# MB9BF51xN register map
File version: 1.8
CPU: 
Registers are 8-bit, read-write, reset 0x0 unless marked. A register's access mark holds for its fields unless they carry their own. Offsets are from the block's base; [hi:lo] are bit positions; {n}, {i} and the like mark numbered series.

## INTREQ — Interrupts
Base 0x40031000
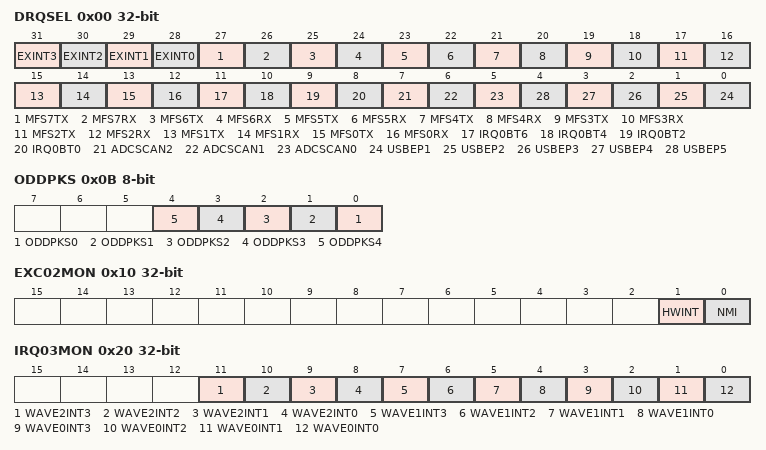
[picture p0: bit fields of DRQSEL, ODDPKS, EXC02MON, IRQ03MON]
0x00 DRQSEL 32-bit — DMA Request Selection Register
  [31] EXINT3 — The interrupt signal of the external interrupt ch.3 is output as a transfer request to the DMAC (including extension).
  [30] EXINT2 — The interrupt signal of the external interrupt ch.2 is output as a transfer request to the DMAC (including extension).
  [29] EXINT1 — The interrupt signal of the external interrupt ch.1 is output as a transfer request to the DMAC (including extension).
  [28] EXINT0 — The interrupt signal of the external interrupt ch.0 is output as a transfer request to the DMAC (including extension).
  [27] MFS7TX — The transmission interrupt signal of the MFS ch.7 is output as a transfer request to the DMAC (including extension).
  [26] MFS7RX — The reception interrupt signal of the MFS ch.7 is output as a transfer request to the DMAC (including extension).
  [25] MFS6TX — The transmission interrupt signal of the MFS ch.6 is output as a transfer request to the DMAC (including extension).
  [24] MFS6RX — The reception interrupt signal of the MFS ch.6 is output as a transfer request to the DMAC (including extension).
  [23] MFS5TX — The transmission interrupt signal of the MFS ch.5 is output as a transfer request to the DMAC (including extension).
  [22] MFS5RX — The reception interrupt signal of the MFS ch.5 is output as a transfer request to the DMAC (including extension).
  [21] MFS4TX — The transmission interrupt signal of the MFS ch.4 is output as a transfer request to the DMAC (including extension).
  [20] MFS4RX — The reception interrupt signal of the MFS ch.4 is output as a transfer request to the DMAC (including extension).
  [19] MFS3TX — The transmission interrupt signal of the MFS ch.3 is output as a transfer request to the DMAC (including extension).
  [18] MFS3RX — The reception interrupt signal of the MFS ch.3 is output as a transfer request to the DMAC (including extension).
  [17] MFS2TX — The transmission interrupt signal of the MFS ch.2 is output as a transfer request to the DMAC (including extension).
  [16] MFS2RX — The reception interrupt signal of the MFS ch.2 is output as a transfer request to the DMAC (including extension).
  [15] MFS1TX — The transmission interrupt signal of the MFS ch.1 is output as a transfer request to the DMAC (including extension).
  [14] MFS1RX — The reception interrupt signal of the MFS ch.1 is output as a transfer request to the DMAC (including extension).
  [13] MFS0TX — The transmission interrupt signal of the MFS ch.0 is output as a transfer request to the DMAC (including extension).
  [12] MFS0RX — The reception interrupt signal of the MFS ch.0 is output as a transfer request to the DMAC (including extension).
  [11] IRQ0BT6 — The IRQ0 interrupt signal of the base timer ch.6 is output as a transfer request to the DMAC.
  [10] IRQ0BT4 — The IRQ0 interrupt signal of the base timer ch.4 is output as a transfer request to the DMAC.
  [9] IRQ0BT2 — The IRQ0 interrupt signal of the base timer ch.3 is output as a transfer request to the DMAC.
  [8] IRQ0BT0 — The IRQ0 interrupt signal of the base timer ch.0 is output as a transfer request to the DMAC.
  [7] ADCSCAN2 — The scan conversion interrupt signal of the A/D converter unit 2 is output as a transfer request to the DMAC.
  [6] ADCSCAN1 — The scan conversion interrupt signal of the A/D converter unit 1 is output as a transfer request to the DMAC.
  [5] ADCSCAN0 — The scan conversion interrupt signal of the A/D converter unit 0 is output as a transfer request to the DMAC.
  [n-1] USBEP{n} (n=1..5) — The EP{n} DRQ interrupt signal of the USB ch.0 is output as a transfer request to the DMAC.
0x0B ODDPKS — USB ch.0 Odd Packet Size DMA Enable Register
  [n] ODDPKS{n} (n=0..4) — "When the transfer destination address of DMAC is USB.EP{n+1}DT, the bit width of the last transfer data is converted to Byte."
0x0C IRQCMODE 32-bit — Interrupt Factor Vector Relocate Setting Register
  [0] IRQCMODE — Interrupt Factor Vector Relocate Setting
0x10 EXC02MON 32-bit ro — EXC02 batch read register
  [1] HWINT — Hardware watchdog timer interrupt request
  [0] NMI — External NMIX pin interrupt request
0x14 IRQ00MON 32-bit ro — IRQ00 Batch Read Register
  [0] FCSINT — Anomalous frequency detection by CSV interrupt request
0x18 IRQ01MON 32-bit ro — IRQ01 Batch Read Register
  [0] SWWDTINT — Software watchdog timer interrupt request
0x1C IRQ02MON 32-bit ro — IRQ02 Batch Read Register
  [0] LVDINT — Low voltage detection (LVD) interrupt request
0x20 IRQ03MON 32-bit ro — IRQ03 Batch Read Register
  [11] WAVE2INT3 — WFG timer 54 interrupt request in MFT unit 2
  [10] WAVE2INT2 — WFG timer 32 interrupt request in MFT unit 2
  [9] WAVE2INT1 — WFG timer 10 interrupt request in MFT unit 2
  [8] WAVE2INT0 — DTIF (motor emergency stop) interrupt request in MFT unit 2
  [7] WAVE1INT3 — WFG timer 54 interrupt request in MFT unit 1
  [6] WAVE1INT2 — WFG timer 32 interrupt request in MFT unit 1
  [5] WAVE1INT1 — WFG timer 10 interrupt request in MFT unit 1
  [4] WAVE1INT0 — DTIF (motor emergency stop) interrupt request in MFT unit 1
  [3] WAVE0INT3 — WFG timer 54 interrupt request in MFT unit 0
  [2] WAVE0INT2 — WFG timer 32 interrupt request in MFT unit 0
  [1] WAVE0INT1 — WFG timer 10 interrupt request in MFT unit 0
  [0] WAVE0INT0 — DTIF (motor emergency stop) interrupt request in MFT unit 0
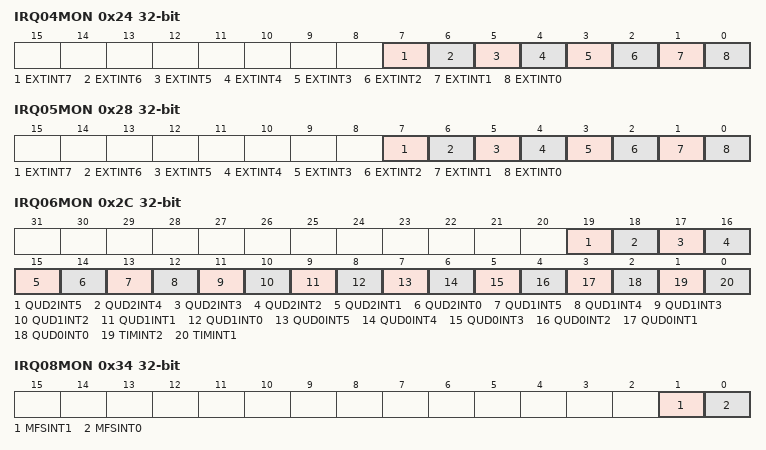
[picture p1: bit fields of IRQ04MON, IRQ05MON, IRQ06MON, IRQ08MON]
0x24 IRQ04MON 32-bit ro — IRQ04 Batch Read Register
  [7] EXTINT7 — Interrupt request on external interrupt ch.7
  [6] EXTINT6 — Interrupt request on external interrupt ch.6
  [5] EXTINT5 — Interrupt request on external interrupt ch.5
  [4] EXTINT4 — Interrupt request on external interrupt ch.4
  [3] EXTINT3 — Interrupt request on external interrupt ch.3
  [2] EXTINT2 — Interrupt request on external interrupt ch.2
  [1] EXTINT1 — Interrupt request on external interrupt ch.1
  [0] EXTINT0 — Interrupt request on external interrupt ch.0
0x28 IRQ05MON 32-bit ro — IRQ05 Batch Read Register
  [7] EXTINT7 — Interrupt request on external interrupt ch.15
  [6] EXTINT6 — Interrupt request on external interrupt ch.14
  [5] EXTINT5 — Interrupt request on external interrupt ch.13
  [4] EXTINT4 — Interrupt request on external interrupt ch.12
  [3] EXTINT3 — Interrupt request on external interrupt ch.11
  [2] EXTINT2 — Interrupt request on external interrupt ch.10
  [1] EXTINT1 — Interrupt request on external interrupt ch.9
  [0] EXTINT0 — Interrupt request on external interrupt ch.8
0x2C IRQ06MON 32-bit ro — IRQ06 Batch Read Register
  [19] QUD2INT5 — PC match and RC match interrupt request on QPRC ch.2
  [18] QUD2INT4 — Interrupt request detected RC out of range on QPRC ch.2
  [17] QUD2INT3 — PC count invert interrupt request on QPRC ch.2
  [16] QUD2INT2 — Overflow/underflow/zero index interrupt request on QPRC ch.2
  [15] QUD2INT1 — PC and RC match interrupt request on QPRC ch.2
  [14] QUD2INT0 — PC match interrupt request on QPRC ch.2
  [13] QUD1INT5 — PC match and RC match interrupt request on QPRC ch.1
  [12] QUD1INT4 — Interrupt request detected RC out of range on QPRC ch.1
  [11] QUD1INT3 — PC count invert interrupt request on QPRC ch.1
  [10] QUD1INT2 — Overflow/underflow/zero index interrupt request on QPRC ch.1
  [9] QUD1INT1 — PC and RC match interrupt request on QPRC ch.1
  [8] QUD1INT0 — PC match interrupt request on QPRC ch.1
  [7] QUD0INT5 — PC match and RC match interrupt request on QPRC ch.0
  [6] QUD0INT4 — Interrupt request detected RC out of range on QPRC ch.0
  [5] QUD0INT3 — PC count invert interrupt request on QPRC ch.0
  [4] QUD0INT2 — Overflow/underflow/zero index interrupt request on QPRC ch.0
  [3] QUD0INT1 — PC and RC match interrupt request on QPRC ch.0
  [2] QUD0INT0 — PC match interrupt request on QPRC ch.0
  [1] TIMINT2 — Dual timer 2 interrupt request
  [0] TIMINT1 — Dual timer 1 interrupt request
0x30 IRQ07MON 32-bit ro — IRQ07 Batch Read Register
  [0] MFSINT — Reception interrupt request on MFS ch.0
0x34 IRQ08MON 32-bit ro — IRQ08 Batch Read Register
  [1] MFSINT1 — Status interrupt request on MFS ch.0
  [0] MFSINT0 — Transmission interrupt request on MFS ch.0
0x38 IRQ09MON 32-bit ro — IRQ09 Batch Read Register
  [0] MFSINT — Reception interrupt request on MFS ch.1
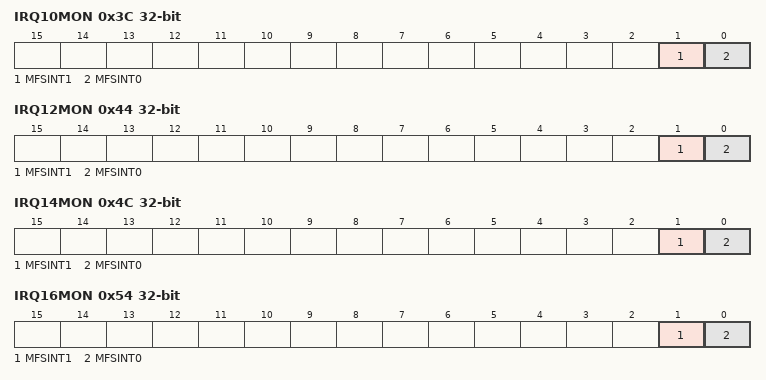
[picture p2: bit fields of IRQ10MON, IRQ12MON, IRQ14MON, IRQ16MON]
0x3C IRQ10MON 32-bit ro — IRQ10 Batch Read Register
  [1] MFSINT1 — Status interrupt request on MFS ch.1
  [0] MFSINT0 — Transmission interrupt request on MFS ch.1
0x40 IRQ11MON 32-bit ro — IRQ11 Batch Read Register
  [0] MFSINT — Reception interrupt request on MFS ch.2
0x44 IRQ12MON 32-bit ro — IRQ12 Batch Read Register
  [1] MFSINT1 — Status interrupt request on MFS ch.2
  [0] MFSINT0 — Transmission interrupt request on MFS ch.2
0x48 IRQ13MON 32-bit ro — IRQ13 Batch Read Register
  [0] MFSINT — Reception interrupt request on MFS ch.3
0x4C IRQ14MON 32-bit ro — IRQ14 Batch Read Register
  [1] MFSINT1 — Status interrupt request on MFS ch.3
  [0] MFSINT0 — Transmission interrupt request on MFS ch.3
0x50 IRQ15MON 32-bit ro — IRQ15 Batch Read Register
  [0] MFSINT — Reception interrupt request on MFS ch.4
0x54 IRQ16MON 32-bit ro — IRQ16 Batch Read Register
  [1] MFSINT1 — Status interrupt request on MFS ch.4
  [0] MFSINT0 — Transmission interrupt request on MFS ch.4
0x58 IRQ17MON 32-bit ro — IRQ17 Batch Read Register
  [0] MFSINT — Reception interrupt request on MFS ch.5
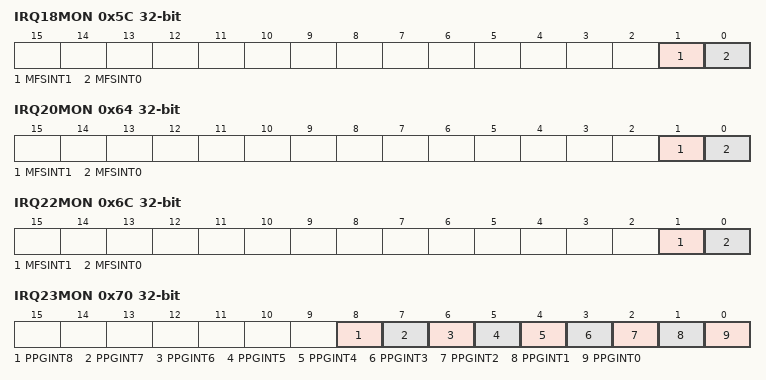
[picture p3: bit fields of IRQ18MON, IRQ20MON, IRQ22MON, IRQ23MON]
0x5C IRQ18MON 32-bit ro — IRQ18 Batch Read Register
  [1] MFSINT1 — Status interrupt request on MFS ch.5
  [0] MFSINT0 — Transmission interrupt request on MFS ch.5
0x60 IRQ19MON 32-bit ro — IRQ19 Batch Read Register
  [0] MFSINT — Reception interrupt request on MFS ch.6
0x64 IRQ20MON 32-bit ro — IRQ20 Batch Read Register
  [1] MFSINT1 — Status interrupt request on MFS ch.6
  [0] MFSINT0 — Transmission interrupt request on MFS ch.6
0x68 IRQ21MON 32-bit ro — IRQ21 Batch Read Register
  [0] MFSINT — Reception interrupt request on MFS ch.7
0x6C IRQ22MON 32-bit ro — IRQ22 Batch Read Register
  [1] MFSINT1 — Status interrupt request on MFS ch.7
  [0] MFSINT0 — Transmission interrupt request on MFS ch.7
0x70 IRQ23MON 32-bit ro — IRQ23 Batch Read Register
  [8] PPGINT8 — Interrupt request on PPG ch.20
  [7] PPGINT7 — Interrupt request on PPG ch.18
  [6] PPGINT6 — Interrupt request on PPG ch.16
  [5] PPGINT5 — Interrupt request on PPG ch.12
  [4] PPGINT4 — Interrupt request on PPG ch.10
  [3] PPGINT3 — Interrupt request on PPG ch.8
  [2] PPGINT2 — Interrupt request on PPG ch.4
  [1] PPGINT1 — Interrupt request on PPG ch.2
  [0] PPGINT0 — Interrupt request on PPG ch.0
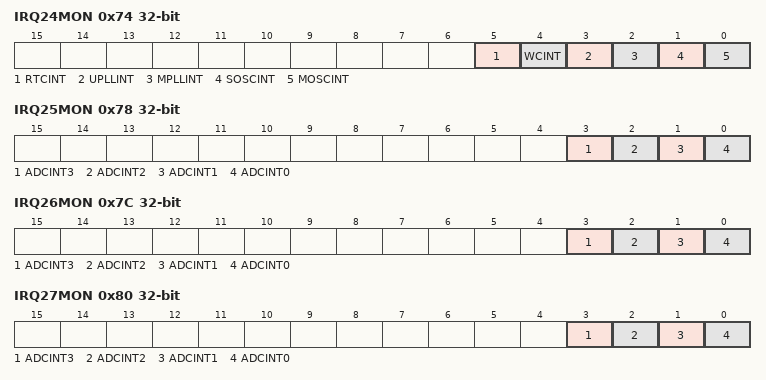
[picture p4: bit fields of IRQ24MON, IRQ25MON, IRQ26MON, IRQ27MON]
0x74 IRQ24MON 32-bit ro — IRQ24 Batch Read Register
  [5] RTCINT — RTC interrupt request
  [4] WCINT — Watch counter interrupt request
  [3] UPLLINT — Stabilization wait completion interrupt request for USB or USB/Ethernet PLL oscillation.
  [2] MPLLINT — Stabilization wait completion interrupt request for main PLL oscillation
  [1] SOSCINT — Stabilization wait completion interrupt request for sub-clock oscillation
  [0] MOSCINT — Stabilization wait completion interrupt request for main clock oscillation
0x78 IRQ25MON 32-bit ro — IRQ25 Batch Read Register
  [3] ADCINT3 — Conversion result comparison interrupt request in the corresponding A/D unit 0.
  [2] ADCINT2 — FIFO overrun interrupt request in the corresponding A/D unit 0.
  [1] ADCINT1 — Scan conversion interrupt request in the corresponding A/D unit 0.
  [0] ADCINT0 — Priority conversion interrupt request in the corresponding A/D unit 0.
0x7C IRQ26MON 32-bit ro — IRQ26 Batch Read Register
  [3] ADCINT3 — Conversion result comparison interrupt request in the corresponding A/D unit 1
  [2] ADCINT2 — FIFO overrun interrupt request in the corresponding A/D unit 1
  [1] ADCINT1 — Scan conversion interrupt request in the corresponding A/D unit 1
  [0] ADCINT0 — Priority conversion interrupt request in the corresponding A/D unit 1
0x80 IRQ27MON 32-bit ro — IRQ27 Batch Read Register
  [3] ADCINT3 — Conversion result comparison interrupt request in the corresponding A/D unit 2
  [2] ADCINT2 — FIFO overrun interrupt request in the corresponding A/D unit 2
  [1] ADCINT1 — Scan conversion interrupt request in the corresponding A/D unit 2
  [0] ADCINT0 — Priority conversion interrupt request in the corresponding A/D unit 2
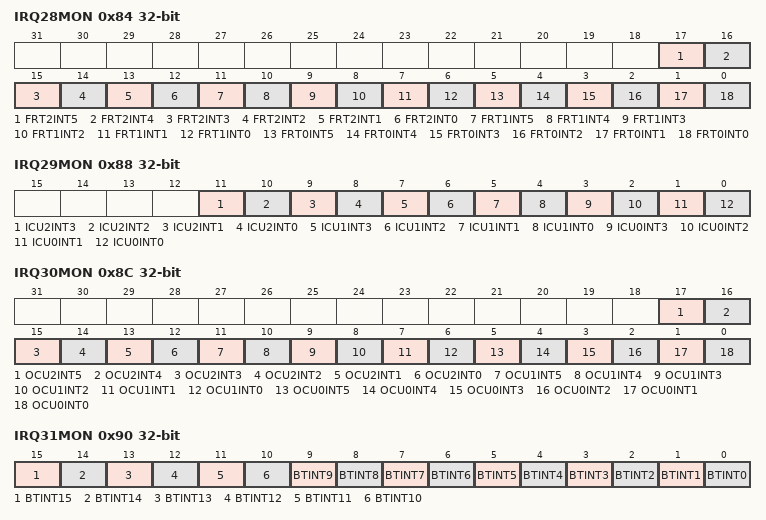
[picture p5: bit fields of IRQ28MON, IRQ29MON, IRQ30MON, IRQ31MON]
0x84 IRQ28MON 32-bit ro — IRQ28 Batch Read Register
  [17] FRT2INT5 — Zero detection interrupt request on the free run timer ch.2 in the MFT unit 2
  [16] FRT2INT4 — Zero detection interrupt request on the free run timer ch.1 in the MFT unit 2
  [15] FRT2INT3 — Zero detection interrupt request on the free run timer ch.0 in the MFT unit 2
  [14] FRT2INT2 — Peak value detection interrupt request on the free run timer ch.2 in the MFT unit 2
  [13] FRT2INT1 — Peak value detection interrupt request on the free run timer ch.1 in the MFT unit 2
  [12] FRT2INT0 — Peak value detection interrupt request on the free run timer ch.0 in the MFT unit 2
  [11] FRT1INT5 — Zero detection interrupt request on the free run timer ch.2 in the MFT unit 1
  [10] FRT1INT4 — Zero detection interrupt request on the free run timer ch.1 in the MFT unit 1
  [9] FRT1INT3 — Zero detection interrupt request on the free run timer ch.0 in the MFT unit 1
  [8] FRT1INT2 — Peak value detection interrupt request on the free run timer ch.2 in the MFT unit 1
  [7] FRT1INT1 — Peak value detection interrupt request on the free run timer ch.1 in the MFT unit 1
  [6] FRT1INT0 — Peak value detection interrupt request on the free run timer ch.0 in the MFT unit 1
  [5] FRT0INT5 — Zero detection interrupt request on the free run timer ch.2 in the MFT unit 0
  [4] FRT0INT4 — Zero detection interrupt request on the free run timer ch.1 in the MFT unit 0
  [3] FRT0INT3 — Zero detection interrupt request on the free run timer ch.0 in the MFT unit 0
  [2] FRT0INT2 — Peak value detection interrupt request on the free run timer ch.2 in the MFT unit 0
  [1] FRT0INT1 — Peak value detection interrupt request on the free run timer ch.1 in the MFT unit 0
  [0] FRT0INT0 — Peak value detection interrupt request on the free run timer ch.0 in the MFT unit 0
0x88 IRQ29MON 32-bit ro — IRQ29 Batch Read Register
  [11] ICU2INT3 — Interrupt request on the input capture ch.3 in the MFT unit 2
  [10] ICU2INT2 — Interrupt request on the input capture ch.2 in the MFT unit 2
  [9] ICU2INT1 — Interrupt request on the input capture ch.1 in the MFT unit 2
  [8] ICU2INT0 — Interrupt request on the input capture ch.0 in the MFT unit 2
  [7] ICU1INT3 — Interrupt request on the input capture ch.3 in the MFT unit 1
  [6] ICU1INT2 — Interrupt request on the input capture ch.2 in the MFT unit 1
  [5] ICU1INT1 — Interrupt request on the input capture ch.1 in the MFT unit 1
  [4] ICU1INT0 — Interrupt request on the input capture ch.0 in the MFT unit 1
  [3] ICU0INT3 — Interrupt request on the input capture ch.3 in the MFT unit 0
  [2] ICU0INT2 — Interrupt request on the input capture ch.2 in the MFT unit 0
  [1] ICU0INT1 — Interrupt request on the input capture ch.1 in the MFT unit 0
  [0] ICU0INT0 — Interrupt request on the input capture ch.0 in the MFT unit 0
0x8C IRQ30MON 32-bit ro — IRQ30 Batch Read Register
  [17] OCU2INT5 — Interrupt request on the output compare ch.5 in the MFT unit 2
  [16] OCU2INT4 — Interrupt request on the output compare ch.4 in the MFT unit 2
  [15] OCU2INT3 — Interrupt request on the output compare ch.3 in the MFT unit 2
  [14] OCU2INT2 — Interrupt request on the output compare ch.2 in the MFT unit 2
  [13] OCU2INT1 — Interrupt request on the output compare ch.1 in the MFT unit 2
  [12] OCU2INT0 — Interrupt request on the output compare ch.0 in the MFT unit 2
  [11] OCU1INT5 — Interrupt request on the output compare ch.5 in the MFT unit 1
  [10] OCU1INT4 — Interrupt request on the output compare ch.4 in the MFT unit 1
  [9] OCU1INT3 — Interrupt request on the output compare ch.3 in the MFT unit 1
  [8] OCU1INT2 — Interrupt request on the output compare ch.2 in the MFT unit 1
  [7] OCU1INT1 — Interrupt request on the output compare ch.1 in the MFT unit 1
  [6] OCU1INT0 — Interrupt request on the output compare ch.0 in the MFT unit 1
  [5] OCU0INT5 — Interrupt request on the output compare ch.5 in the MFT unit 0
  [4] OCU0INT4 — Interrupt request on the output compare ch.4 in the MFT unit 0
  [3] OCU0INT3 — Interrupt request on the output compare ch.3 in the MFT unit 0
  [2] OCU0INT2 — Interrupt request on the output compare ch.2 in the MFT unit 0
  [1] OCU0INT1 — Interrupt request on the output compare ch.1 in the MFT unit 0
  [0] OCU0INT0 — Interrupt request on the output compare ch.0 in the MFT unit 0
0x90 IRQ31MON 32-bit ro — IRQ31 Batch Read Register
  [15] BTINT15 — IRQ1 interrupt request on the base timer ch.7
  [14] BTINT14 — IRQ0 interrupt request on the base timer ch.7
  [13] BTINT13 — IRQ1 interrupt request on the base timer ch.6
  [12] BTINT12 — IRQ0 interrupt request on the base timer ch.6
  [11] BTINT11 — IRQ1 interrupt request on the base timer ch.5
  [10] BTINT10 — IRQ0 interrupt request on the base timer ch.5
  [9] BTINT9 — IRQ1 interrupt request on the base timer ch.4
  [8] BTINT8 — IRQ0 interrupt request on the base timer ch.4
  [7] BTINT7 — IRQ1 interrupt request on the base timer ch.3
  [6] BTINT6 — IRQ0 interrupt request on the base timer ch.3
  [5] BTINT5 — IRQ1 interrupt request on the base timer ch.2
  [4] BTINT4 — IRQ0 interrupt request on the base timer ch.2
  [3] BTINT3 — IRQ1 interrupt request on the base timer ch.1
  [2] BTINT2 — IRQ0 interrupt request on the base timer ch.1
  [1] BTINT1 — IRQ1 interrupt request on the base timer ch.0
  [0] BTINT0 — IRQ0 interrupt request on the base timer ch.0
0x94 IRQ32MON 32-bit ro — IRQ32 Batch Read Register
  [0] CAN0INT — Interrupt request of CAN ch.0
0x98 IRQ33MON 32-bit ro — IRQ33 Batch Read Register
  [0] CAN1INT — Interrupt request of CAN ch.1
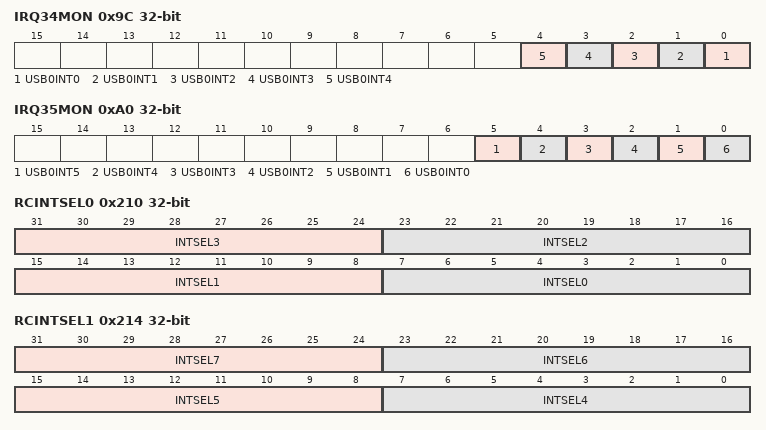
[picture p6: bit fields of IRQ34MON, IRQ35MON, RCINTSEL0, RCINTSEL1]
0x9C IRQ34MON 32-bit ro — IRQ34 Batch Read Register
  [n] USB0INT{n} (n=0..4) — Endpoint {n+1} DRQ interrupt request on the USB ch.0
0xA0 IRQ35MON 32-bit ro — IRQ35 Batch Read Register
  [5] USB0INT5 — "Status (SOFIRQ, CMPIRO) interrupt request on the USB ch.0 "
  [4] USB0INT4 — "Status (DIRQ, URIRQ, RWKIRQ, CNNIRQ) interrupt request on the USB ch.0 "
  [3] USB0INT3 — Status (SPK) interrupt request on the USB ch.0
  [2] USB0INT2 — "Status (SUSP, SOF, BRST, CONF, WKUP) interrupt request on the USB ch.0 "
  [1] USB0INT1 — Endpoint 0 DRQO interrupt request on the USB ch.0
  [0] USB0INT0 — Endpoint 0 DRQI interrupt request on the USB ch.0
0xAC IRQ38MON 32-bit ro — IRQ38 Batch Read Register
  [0] DMAINT — Interrupt request on DMA ch.0.
0xB0 IRQ39MON 32-bit ro — IRQ39 Batch Read Register
  [0] DMAINT — Interrupt request on DMA ch.1.
0xB4 IRQ40MON 32-bit ro — IRQ40 Batch Read Register
  [0] DMAINT — Interrupt request on DMA ch.2.
0xB8 IRQ41MON 32-bit ro — IRQ41 Batch Read Register
  [0] DMAINT — Interrupt request on DMA ch.3.
0xBC IRQ42MON 32-bit ro — IRQ42 Batch Read Register
  [0] DMAINT — Interrupt request on DMA ch.4.
0xC0 IRQ43MON 32-bit ro — IRQ43 Batch Read Register
  [0] DMAINT — Interrupt request on DMA ch.5.
0xC4 IRQ44MON 32-bit ro — IRQ44 Batch Read Register
  [0] DMAINT — Interrupt request on DMA ch.6.
0xC8 IRQ45MON 32-bit ro — IRQ45 Batch Read Register
  [0] DMAINT — Interrupt request on DMA ch.7.
0x210 RCINTSEL0 32-bit — Interrupt Factor Selection Register 0
  [31:24] INTSEL3 — select the interrupt factor of the interrupt vector No.22.
  [23:16] INTSEL2 — select the interrupt factor of the interrupt vector No.21.
  [15:8] INTSEL1 — select the interrupt factor of the interrupt vector No.20.
  [7:0] INTSEL0 — select the interrupt factor of the interrupt vector No.19.
0x214 RCINTSEL1 32-bit — Interrupt Factor Selection Register 1
  [31:24] INTSEL7 — select the interrupt factor of the interrupt vector No.26.
  [23:16] INTSEL6 — select the interrupt factor of the interrupt vector No.25.
  [15:8] INTSEL5 — select the interrupt factor of the interrupt vector No.24.
  [7:0] INTSEL4 — select the interrupt factor of the interrupt vector No.23.
